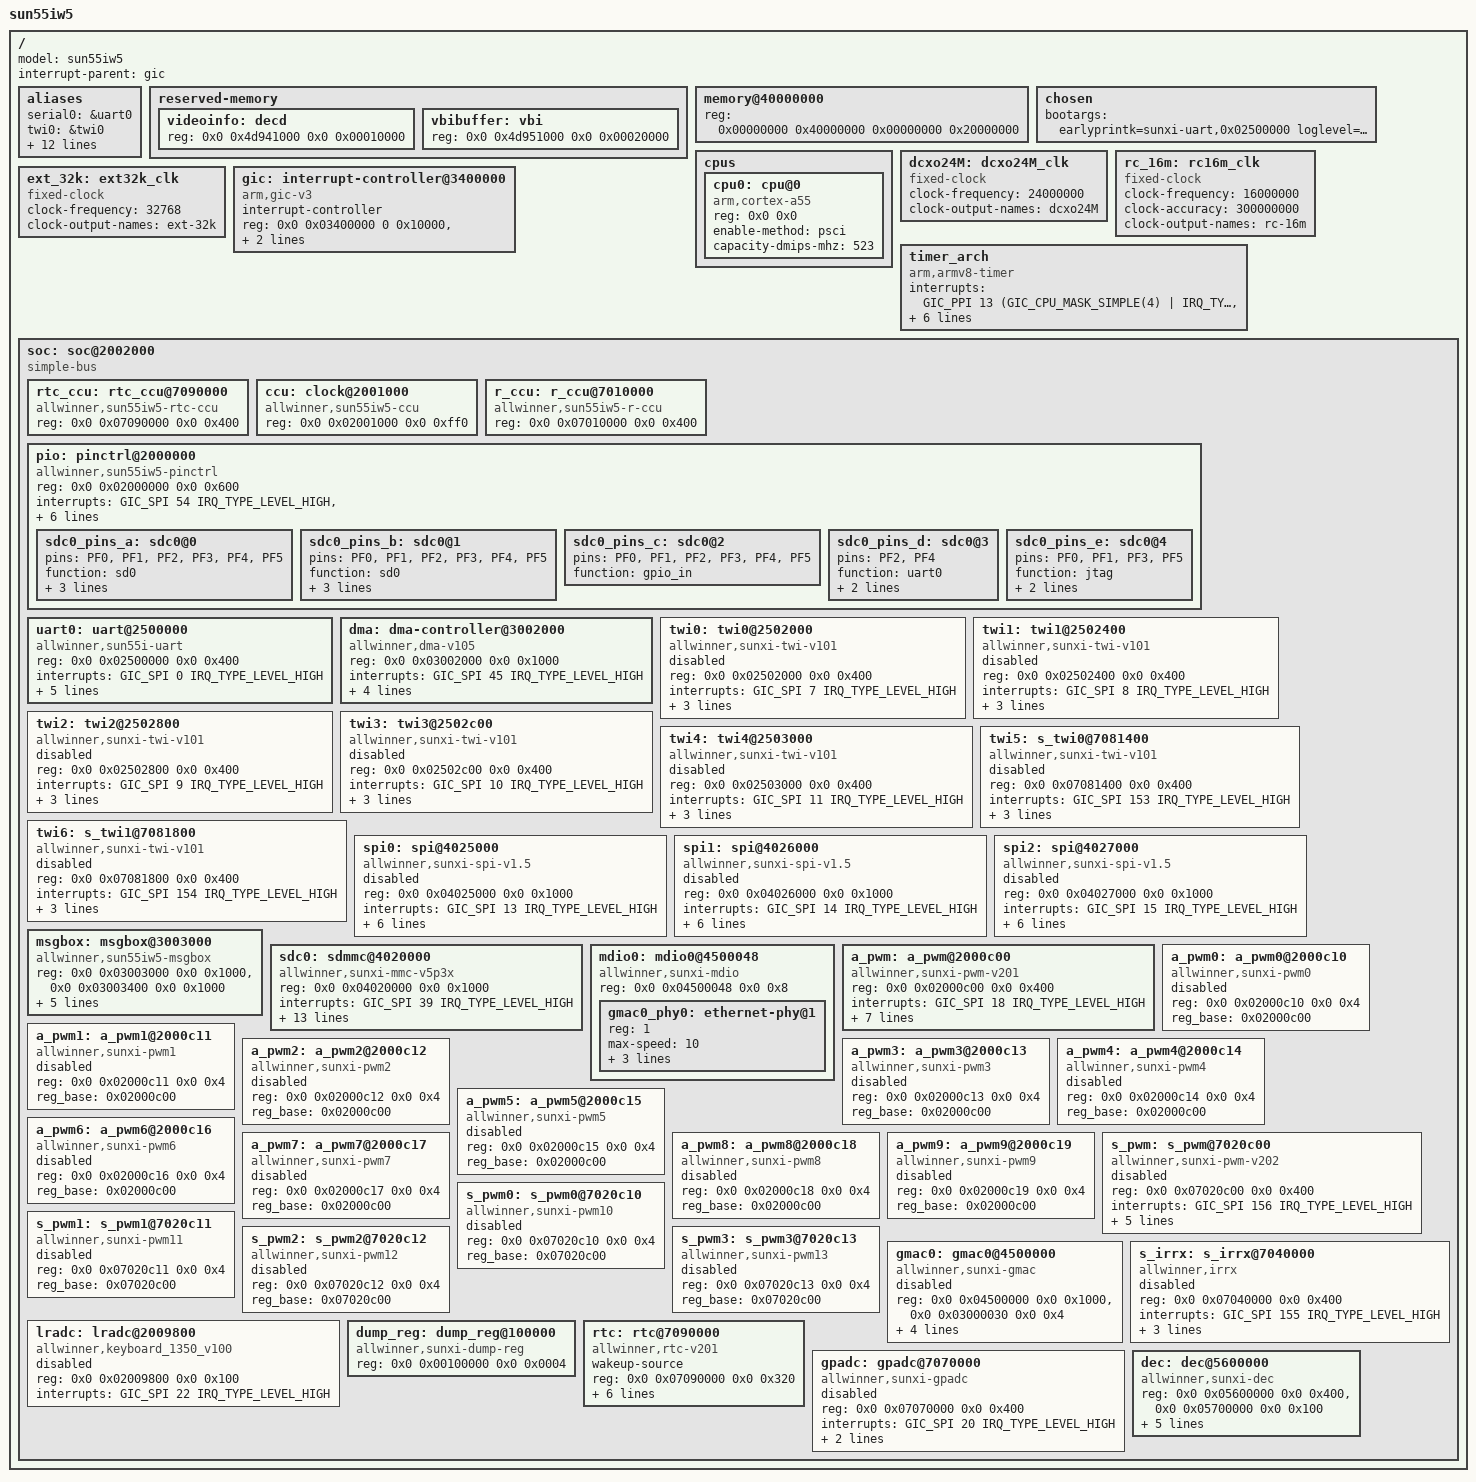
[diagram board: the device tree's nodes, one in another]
// SPDX-License-Identifier: (GPL-2.0+ or MIT)
/*
 * Copyright (C) 2023 zhaozeyan@allwinnertech.com
 */

#include <dt-bindings/clock/sun55iw5-ccu.h>
#include <dt-bindings/clock/sun55iw5-rtc.h>
#include <dt-bindings/clock/sun55iw5-r-ccu.h>
#include <dt-bindings/reset/sun55iw5-ccu.h>
#include <dt-bindings/reset/sun55iw5-r-ccu.h>
#include <dt-bindings/gpio/gpio.h>
#include <dt-bindings/gpio/sun4i-gpio.h>
#include <dt-bindings/interrupt-controller/arm-gic.h>
#include <dt-bindings/thermal/thermal.h>
#include <dt-bindings/spi/sunxi-spi.h>

/ {
	model = "sun55iw5";
	interrupt-parent = <&gic>;
	#address-cells = <2>;
	#size-cells = <2>;

	aliases {
		serial0 = &uart0;
		twi0 = &twi0;
		twi1 = &twi1;
		twi2 = &twi2;
		twi3 = &twi3;
		twi4 = &twi4;
		twi5 = &twi5;
		twi6 = &twi6;
		spi0 = &spi0;
		spi1 = &spi1;
		spi2 = &spi2;
		ir1 = &s_irrx;
		gpadc0 = &gpadc;
		dec = &dec;
	};

	reserved-memory {
		#address-cells = <2>;
		#size-cells = <2>;
		ranges;
		videoinfo: decd {
			reg = <0x0 0x4d941000 0x0 0x00010000>;
		};
		vbibuffer: vbi {
			reg = <0x0 0x4d951000 0x0 0x00020000>;
		};
	};

	memory@40000000 {
		device_type = "memory";
		reg = <0x00000000 0x40000000 0x00000000 0x20000000>;
	};

	chosen {
		bootargs = "earlyprintk=sunxi-uart,0x02500000 loglevel=8 initcall_debug=1 console=ttyS0 init=/init";
	};

	cpus {
		#address-cells = <2>;
		#size-cells = <0>;

		cpu0: cpu@0 {
			device_type = "cpu";
			compatible = "arm,cortex-a55";
			reg = <0x0 0x0>;
			enable-method = "psci";
			capacity-dmips-mhz = <523>;
		};
	};

	dcxo24M: dcxo24M_clk {
		#clock-cells = <0>;
		compatible = "fixed-clock";
		clock-frequency = <24000000>;
		clock-output-names = "dcxo24M";
	};

	rc_16m: rc16m_clk {
		#clock-cells = <0>;
		compatible = "fixed-clock";
		clock-frequency = <16000000>;
		clock-accuracy = <300000000>;
		clock-output-names = "rc-16m";
	};

	ext_32k: ext32k_clk {
		#clock-cells = <0>;
		compatible = "fixed-clock";
		clock-frequency = <32768>;
		clock-output-names = "ext-32k";
	};

	gic: interrupt-controller@3400000 {
		compatible = "arm,gic-v3";
		#interrupt-cells = <3>;
		#address-cells = <0>;
		interrupt-controller;
		reg = <0x0 0x03400000 0 0x10000>, /* GIC Dist */
		      <0x0 0x03440000 0 0xFF004>; /* GIC Re */
		interrupt-parent = <&gic>;
	};

	timer_arch {
		compatible = "arm,armv8-timer";
		interrupts = <GIC_PPI 13 (GIC_CPU_MASK_SIMPLE(4) | IRQ_TYPE_LEVEL_LOW)>,
			   <GIC_PPI 14 (GIC_CPU_MASK_SIMPLE(4) | IRQ_TYPE_LEVEL_LOW)>,
			   <GIC_PPI 11 (GIC_CPU_MASK_SIMPLE(4) | IRQ_TYPE_LEVEL_LOW)>,
			   <GIC_PPI 10 (GIC_CPU_MASK_SIMPLE(4) | IRQ_TYPE_LEVEL_LOW)>;
		clock-frequency = <24000000>;
		interrupt-parent = <&gic>;
		arm,no-tick-in-suspend;
	};

	soc: soc@2002000 {
		compatible = "simple-bus";
		#address-cells = <2>;
		#size-cells = <2>;
		ranges;
		device_type = "soc";

		rtc_ccu: rtc_ccu@7090000 {
			compatible = "allwinner,sun55iw5-rtc-ccu";
			reg = <0x0 0x07090000 0x0 0x400>;
			#clock-cells = <1>;
			#reset-cells = <1>;
		};

		ccu: clock@2001000 {
			compatible = "allwinner,sun55iw5-ccu";
			reg = <0x0 0x02001000 0x0 0xff0>;
			#clock-cells = <1>;
			#reset-cells = <1>;
		};

		r_ccu: r_ccu@7010000 {
			compatible = "allwinner,sun55iw5-r-ccu";
			reg = <0x0 0x07010000 0x0 0x400>;
			#clock-cells = <1>;
			#reset-cells = <1>;
		};

		pio: pinctrl@2000000 {
			compatible = "allwinner,sun55iw5-pinctrl";
			reg = <0x0 0x02000000 0x0 0x600>;
			interrupts = <GIC_SPI 54 IRQ_TYPE_LEVEL_HIGH>,
				   <GIC_SPI 58 IRQ_TYPE_LEVEL_HIGH>,
				   <GIC_SPI 60 IRQ_TYPE_LEVEL_HIGH>;
			clocks = <&ccu CLK_APB1>, <&dcxo24M>, <&ext_32k>;
			clock-names = "apb", "hosc", "losc";
			device_type = "pio";
			gpio-controller;
			interrupt-controller;
			#interrupt-cells = <3>;
			#address-cells = <0>;
			#gpio-cells = <3>;
			input-debounce = <0 0 0 0 1000 0 0 0 0>;

			sdc0_pins_a: sdc0@0 {
				pins = "PF0", "PF1", "PF2",
						"PF3", "PF4", "PF5";
				function = "sd0";
				drive-strength = <40>;
				bias-pull-up;
				power-source = <3300>;
			};

			sdc0_pins_b: sdc0@1 {
				pins = "PF0", "PF1", "PF2",
						"PF3", "PF4", "PF5";
				function = "sd0";
				drive-strength = <40>;
				bias-pull-up;
				power-source = <1800>;
			};

			sdc0_pins_c: sdc0@2 {
				pins = "PF0", "PF1", "PF2",
						"PF3", "PF4", "PF5";
				function = "gpio_in";
			};

			/* TODO: add jtag pin */
			sdc0_pins_d: sdc0@3 {
				pins = "PF2", "PF4";
				function = "uart0";
				drive-strength = <10>;
				bias-pull-up;
			};

			sdc0_pins_e: sdc0@4 {
				pins = "PF0", "PF1", "PF3",
						"PF5";
				function = "jtag";
				drive-strength = <10>;
				bias-pull-up;
			};

		};

		uart0: uart@2500000 {
			compatible = "allwinner,sun55i-uart";
			device_type = "uart0";
			reg = <0x0 0x02500000 0x0 0x400>;
			interrupts = <GIC_SPI 0 IRQ_TYPE_LEVEL_HIGH>;
			sunxi,uart-fifosize = <64>;
			clocks = <&ccu CLK_BUS_UART0>;
			clock-names = "uart0";
			resets = <&ccu RST_BUS_UART0>;
			uart0_port = <0>;
			uart0_type = <2>;
			status = "okay";
		};

		dma:dma-controller@3002000 {
			compatible = "allwinner,dma-v105";
			reg = <0x0 0x03002000 0x0 0x1000>;
			interrupts = <GIC_SPI 45 IRQ_TYPE_LEVEL_HIGH>;
			clocks = <&ccu CLK_DMA>, <&ccu CLK_MBUS_DMA>;
			clock-names = "bus", "mbus";
			dma-channels = <8>;
			dma-requests = <54>;
			resets = <&ccu RST_BUS_DMA>;
			#dma-cells = <1>;
			status = "okay";
		};

		twi0: twi0@2502000 {
			#address-cells = <1>;
			#size-cells = <0>;
			compatible = "allwinner,sunxi-twi-v101";
			device_type = "twi0";
			reg = <0x0 0x02502000 0x0 0x400>;
			interrupts = <GIC_SPI 7 IRQ_TYPE_LEVEL_HIGH>;
			clocks = <&ccu CLK_TWI0>;
			clock-names = "bus";
			resets = <&ccu RST_BUS_TWI0>;
			dmas = <&dma 43>, <&dma 43>;
			dma-names = "tx", "rx";
			status = "disabled";
		};

		twi1: twi1@2502400 {
			#address-cells = <1>;
			#size-cells = <0>;
			compatible = "allwinner,sunxi-twi-v101";
			device_type = "twi1";
			reg = <0x0 0x02502400 0x0 0x400>;
			interrupts = <GIC_SPI 8 IRQ_TYPE_LEVEL_HIGH>;
			clocks = <&ccu CLK_TWI1>;
			clock-names = "bus";
			resets = <&ccu RST_BUS_TWI1>;
			dmas = <&dma 44>, <&dma 44>;
			dma-names = "tx", "rx";
			status = "disabled";
		};

		twi2: twi2@2502800 {
			#address-cells = <1>;
			#size-cells = <0>;
			compatible = "allwinner,sunxi-twi-v101";
			device_type = "twi2";
			reg = <0x0 0x02502800 0x0 0x400>;
			interrupts = <GIC_SPI 9 IRQ_TYPE_LEVEL_HIGH>;
			clocks = <&ccu CLK_TWI2>;
			clock-names = "bus";
			resets = <&ccu RST_BUS_TWI2>;
			dmas = <&dma 45>, <&dma 45>;
			dma-names = "tx", "rx";
			status = "disabled";
		};

		twi3: twi3@2502c00 {
			#address-cells = <1>;
			#size-cells = <0>;
			compatible = "allwinner,sunxi-twi-v101";
			device_type = "twi3";
			reg = <0x0 0x02502c00 0x0 0x400>;
			interrupts = <GIC_SPI 10 IRQ_TYPE_LEVEL_HIGH>;
			clocks = <&ccu CLK_TWI3>;
			clock-names = "bus";
			resets = <&ccu RST_BUS_TWI3>;
			dmas = <&dma 46>, <&dma 46>;
			dma-names = "tx", "rx";
			status = "disabled";
		};

		twi4: twi4@2503000 {
			#address-cells = <1>;
			#size-cells = <0>;
			compatible = "allwinner,sunxi-twi-v101";
			device_type = "twi4";
			reg = <0x0 0x02503000 0x0 0x400>;
			interrupts = <GIC_SPI 11 IRQ_TYPE_LEVEL_HIGH>;
			clocks = <&ccu CLK_TWI4>;
			clock-names = "bus";
			resets = <&ccu RST_BUS_TWI4>;
			dmas = <&dma 47>, <&dma 47>;
			dma-names = "tx", "rx";
			status = "disabled";
		};

		twi5: s_twi0@7081400 {
			#address-cells = <1>;
			#size-cells = <0>;
			compatible = "allwinner,sunxi-twi-v101";
			device_type = "twi5";
			reg = <0x0 0x07081400 0x0 0x400>;
			interrupts = <GIC_SPI 153 IRQ_TYPE_LEVEL_HIGH>;
			clocks = <&r_ccu CLK_R_TWI0>;
			clock-names = "bus";
			resets = <&r_ccu RST_BUS_R_TWI0>;
			dmas = <&dma 50>, <&dma 50>;
			dma-names = "tx", "rx";
			status = "disabled";
		};

		twi6: s_twi1@7081800 {
			#address-cells = <1>;
			#size-cells = <0>;
			compatible = "allwinner,sunxi-twi-v101";
			device_type = "twi6";
			reg = <0x0 0x07081800 0x0 0x400>;
			interrupts = <GIC_SPI 154 IRQ_TYPE_LEVEL_HIGH>;
			clocks = <&r_ccu CLK_R_TWI1>;
			clock-names = "bus";
			resets = <&r_ccu RST_BUS_R_TWI1>;
			dmas = <&dma 51>, <&dma 51>;
			dma-names = "tx", "rx";
			status = "disabled";
		};

		spi0: spi@4025000 {
			#address-cells = <1>;
			#size-cells = <0>;
			compatible = "allwinner,sunxi-spi-v1.5";
			reg = <0x0 0x04025000 0x0 0x1000>;
			interrupts = <GIC_SPI 13 IRQ_TYPE_LEVEL_HIGH>;
			clocks = <&ccu CLK_PLL_PERI0_300M>, <&ccu CLK_SPI0>, <&ccu CLK_BUS_SPI0>, <&ccu CLK_AHB>;
			clock-names = "pll", "mod", "bus", "ahb";
			resets = <&ccu RST_BUS_SPI0>;
			dmas = <&dma 22>, <&dma 22>;
			dma-names = "tx", "rx";
			clock-frequency = <100000000>;
			sunxi,spi-num-cs = <2>;
			status = "disabled";
		};

		spi1: spi@4026000 {
			#address-cells = <1>;
			#size-cells = <0>;
			compatible = "allwinner,sunxi-spi-v1.5";
			reg = <0x0 0x04026000 0x0 0x1000>;
			interrupts = <GIC_SPI 14 IRQ_TYPE_LEVEL_HIGH>;
			clocks = <&ccu CLK_PLL_PERI0_300M>, <&ccu CLK_SPI1>, <&ccu CLK_BUS_SPI1>, <&ccu CLK_AHB>;
			clock-names = "pll", "mod", "bus", "ahb";
			resets = <&ccu RST_BUS_SPI1>;
			dmas = <&dma 23>, <&dma 23>;
			dma-names = "tx", "rx";
			clock-frequency = <100000000>;
			sunxi,spi-num-cs = <1>;
			status = "disabled";
		};

		spi2: spi@4027000 {
			#address-cells = <1>;
			#size-cells = <0>;
			compatible = "allwinner,sunxi-spi-v1.5";
			reg = <0x0 0x04027000 0x0 0x1000>;
			interrupts = <GIC_SPI 15 IRQ_TYPE_LEVEL_HIGH>;
			clocks = <&ccu CLK_PLL_PERI0_300M>, <&ccu CLK_SPI2>, <&ccu CLK_BUS_SPI2>, <&ccu CLK_AHB>;
			clock-names = "pll", "mod", "bus", "ahb";
			resets = <&ccu RST_BUS_SPI2>;
			dmas = <&dma 24>, <&dma 24>;
			dma-names = "tx", "rx";
			clock-frequency = <100000000>;
			sunxi,spi-num-cs = <1>;
			status = "disabled";
		};

		/*
		 * channel0~3  : arm -> cpus
		 */
		msgbox: msgbox@3003000 {
			compatible = "allwinner,sun55iw5-msgbox";
			#mbox-cells = <1>;
			reg = <0x0 0x03003000 0x0 0x1000>,
			      <0x0 0x03003400 0x0 0x1000>;
			interrupts = <GIC_SPI 46 IRQ_TYPE_LEVEL_HIGH>,
					<GIC_SPI 108 IRQ_TYPE_LEVEL_HIGH>;
			clocks = <&ccu CLK_MSGBOX>;
			clock-names = "msgbox";
			resets = <&ccu RST_BUS_MSGBOX>;
			reset-names = "rst";
			local_id = <0>;
			status = "okay";
		};

		sdc0: sdmmc@4020000 {
			compatible = "allwinner,sunxi-mmc-v5p3x";
			device_type = "sdc0";
			reg = <0x0 0x04020000 0x0 0x1000>;
			interrupts = <GIC_SPI 39 IRQ_TYPE_LEVEL_HIGH>;
			clocks = <&dcxo24M>,
				 <&ccu CLK_SMHC0>,
				 <&ccu CLK_BUS_SMHC0>;
			clock-names = "osc24m","mmc","ahb";
			resets = <&ccu RST_BUS_SMHC0>;
			reset-names = "rst";
			pinctrl-names = "default","mmc_1v8","sleep","uart_jtag";
			pinctrl-0 = <&sdc0_pins_a>;
			pinctrl-1 = <&sdc0_pins_b>;
			pinctrl-2 = <&sdc0_pins_c>;
			pinctrl-3 = <&sdc0_pins_d &sdc0_pins_e>;
			max-frequency = <50000000>;
			bus-width = <4>;
			req-page-count = <2>;
			/*non-removable;*/
			/*broken-cd;*/
			/*cd-inverted*/
			/*cd-gpios = <&pio PF 6 GPIO_ACTIVE_LOW>;*/
			/* vmmc-supply = <&reg_3p3v>;*/
			/* vqmc-supply = <&reg_3p3v>;*/
			/* vdmc-supply = <&reg_3p3v>;*/
			/*vmmc = "vcc-card";*/
			/*vqmc = "";*/
			/*vdmc = "";*/
			cap-sd-highspeed;
			cap-wait-while-busy;
			/*sd-uhs-sdr50;*/
			/*sd-uhs-ddr50;*/
			/*cap-sdio-irq;*/
			/*keep-power-in-suspend;*/
			/*ignore-pm-notify;*/
			/*sunxi-power-save-mode;*/
			/*sunxi-dly-400k = <1 0 0 0>; */
			/*sunxi-dly-26M  = <1 0 0 0>;*/
			/*sunxi-dly-52M  = <1 0 0 0>;*/
			/*sunxi-dly-52M-ddr4  = <1 0 0 0>;*/
			/*sunxi-dly-52M-ddr8  = <1 0 0 0>;*/
			/*sunxi-dly-104M  = <1 0 0 0>;*/
			/*sunxi-dly-208M  = <1 0 0 0>;*/
			/*sunxi-dly-104M-ddr  = <1 0 0 0>;*/
			/*sunxi-dly-208M-ddr  = <1 0 0 0>;*/
			ctl-spec-caps = <0x408>;
			status = "okay";
		};

		mdio0: mdio0@4500048 {
			compatible = "allwinner,sunxi-mdio";
			#address-cells = <1>;
			#size-cells = <0>;
			reg = <0x0 0x04500048 0x0 0x8>;
			status = "okay";
			gmac0_phy0: ethernet-phy@1 {
				/* RTL8211F (0x001cc916) */
				reg = <1>;
				max-speed = <10>;  /* Max speed capability in FPGA */
				reset-gpios = <&pio PA 14 GPIO_ACTIVE_LOW>;
				/* PHY datasheet rst time */
				reset-assert-us = <10000>;
				reset-deassert-us = <150000>;
			};
		};

		a_pwm: a_pwm@2000c00 {
			#pwm-cells = <0x3>;
			compatible = "allwinner,sunxi-pwm-v201";
			reg = <0x0 0x02000c00 0x0 0x400>;
			interrupts = <GIC_SPI 18 IRQ_TYPE_LEVEL_HIGH>;
			clocks = <&ccu CLK_PWM>;
			resets = <&ccu RST_BUS_PWM>;
			pwm-number = <10>;
			pwm-base = <0x0>;
			sunxi-pwms = <&a_pwm0>, <&a_pwm1>, <&a_pwm2>, <&a_pwm3>,
			<&a_pwm4>, <&a_pwm5>, <&a_pwm6>, <&a_pwm7>, <&a_pwm8>, <&a_pwm9>;
			status = "okay";
		};

		a_pwm0: a_pwm0@2000c10 {
			compatible = "allwinner,sunxi-pwm0";
			pinctrl-names = "active", "sleep";
			reg = <0x0 0x02000c10 0x0 0x4>;
			reg_base = <0x02000c00>;
			status = "disabled";
		};

		a_pwm1: a_pwm1@2000c11 {
			compatible = "allwinner,sunxi-pwm1";
			pinctrl-names = "active", "sleep";
			reg = <0x0 0x02000c11 0x0 0x4>;
			reg_base = <0x02000c00>;
			status = "disabled";
		};

		a_pwm2: a_pwm2@2000c12 {
			compatible = "allwinner,sunxi-pwm2";
			pinctrl-names = "active", "sleep";
			reg = <0x0 0x02000c12 0x0 0x4>;
			reg_base = <0x02000c00>;
			status = "disabled";
		};

		a_pwm3: a_pwm3@2000c13 {
			compatible = "allwinner,sunxi-pwm3";
			pinctrl-names = "active", "sleep";
			reg = <0x0 0x02000c13 0x0 0x4>;
			reg_base = <0x02000c00>;
			status = "disabled";
		};

		a_pwm4: a_pwm4@2000c14 {
			compatible = "allwinner,sunxi-pwm4";
			pinctrl-names = "active", "sleep";
			reg = <0x0 0x02000c14 0x0 0x4>;
			reg_base = <0x02000c00>;
			status = "disabled";
		};

		a_pwm5: a_pwm5@2000c15 {
			compatible = "allwinner,sunxi-pwm5";
			pinctrl-names = "active", "sleep";
			reg = <0x0 0x02000c15 0x0 0x4>;
			reg_base = <0x02000c00>;
			status = "disabled";
		};

		a_pwm6: a_pwm6@2000c16 {
			compatible = "allwinner,sunxi-pwm6";
			pinctrl-names = "active", "sleep";
			reg = <0x0 0x02000c16 0x0 0x4>;
			reg_base = <0x02000c00>;
			status = "disabled";
		};

		a_pwm7: a_pwm7@2000c17 {
			compatible = "allwinner,sunxi-pwm7";
			pinctrl-names = "active", "sleep";
			reg = <0x0 0x02000c17 0x0 0x4>;
			reg_base = <0x02000c00>;
			status = "disabled";
		};

		a_pwm8: a_pwm8@2000c18 {
			compatible = "allwinner,sunxi-pwm8";
			pinctrl-names = "active", "sleep";
			reg = <0x0 0x02000c18 0x0 0x4>;
			reg_base = <0x02000c00>;
			status = "disabled";
		};

		a_pwm9: a_pwm9@2000c19 {
			compatible = "allwinner,sunxi-pwm9";
			pinctrl-names = "active", "sleep";
			reg = <0x0 0x02000c19 0x0 0x4>;
			reg_base = <0x02000c00>;
			status = "disabled";
		};

		s_pwm: s_pwm@7020c00 {
			#pwm-cells = <0x3>;
			compatible = "allwinner,sunxi-pwm-v202";
			reg = <0x0 0x07020c00 0x0 0x400>;
			interrupts = <GIC_SPI 156 IRQ_TYPE_LEVEL_HIGH>;
			clocks = <&r_ccu CLK_R_PWM>,<&r_ccu CLK_BUS_R_PWM>;
			clock-names = "clk_pwm","clk_bus_pwm";
			resets = <&r_ccu RST_BUS_R_PWM>;
			pwm-number = <2>;
			pwm-base = <0xb>;
			sunxi-pwms = <&s_pwm0>, <&s_pwm1>, <&s_pwm2>, <&s_pwm3>;
			status = "disabled";
		};

		s_pwm0: s_pwm0@7020c10 {
			compatible = "allwinner,sunxi-pwm10";
			pinctrl-names = "active", "sleep";
			reg = <0x0 0x07020c10 0x0 0x4>;
			reg_base = <0x07020c00>;
			status = "disabled";
		};

		s_pwm1: s_pwm1@7020c11 {
			compatible = "allwinner,sunxi-pwm11";
			pinctrl-names = "active", "sleep";
			reg = <0x0 0x07020c11 0x0 0x4>;
			reg_base = <0x07020c00>;
			status = "disabled";
		};

		s_pwm2: s_pwm2@7020c12 {
			compatible = "allwinner,sunxi-pwm12";
			pinctrl-names = "active", "sleep";
			reg = <0x0 0x07020c12 0x0 0x4>;
			reg_base = <0x07020c00>;
			status = "disabled";
		};

		s_pwm3: s_pwm3@7020c13 {
			compatible = "allwinner,sunxi-pwm13";
			pinctrl-names = "active", "sleep";
			reg = <0x0 0x07020c13 0x0 0x4>;
			reg_base = <0x07020c00>;
			status = "disabled";
		};

		gmac0: gmac0@4500000 {
			compatible = "allwinner,sunxi-gmac";
			reg = <0x0 0x04500000 0x0 0x1000>,
			      <0x0 0x03000030 0x0 0x4>;
			interrupts = <GIC_SPI 16 IRQ_TYPE_LEVEL_HIGH>;
			interrupt-names = "gmacirq";
			clocks = <&ccu CLK_GMAC0>, <&ccu CLK_GMAC0_25M>;
			clock-names = "gmac", "phy25m";
			resets = <&ccu RST_BUS_GMAC0>;
			phy-handle = <&gmac0_phy0>;
			status = "disabled";
		};

		s_irrx: s_irrx@7040000 {
			compatible = "allwinner,irrx";
			reg = <0x0 0x07040000 0x0 0x400>;
			interrupts = <GIC_SPI 155 IRQ_TYPE_LEVEL_HIGH>;
			clocks = <&r_ccu CLK_BUS_R_IRRX>, <&dcxo24M>, <&r_ccu CLK_R_IRRX>;
			clock-names = "bus", "pclk", "mclk";
			resets = <&r_ccu RST_BUS_R_IRRX>;
			status = "disabled";
		};

		lradc: lradc@2009800 {
			compatible = "allwinner,keyboard_1350_v100";
			reg = <0x0 0x02009800 0x0 0x100>;
			interrupts = <GIC_SPI 22 IRQ_TYPE_LEVEL_HIGH>;
			status = "disabled";
		};

		dump_reg:dump_reg@100000 {
			 compatible = "allwinner,sunxi-dump-reg";
			 reg = <0x0 0x00100000 0x0 0x0004>;
		};

		rtc: rtc@7090000 {
			compatible = "allwinner,rtc-v201";
			device_type = "rtc";
			wakeup-source;
			reg = <0x0 0x07090000 0x0 0x320>;
			interrupts = <GIC_SPI 147 IRQ_TYPE_LEVEL_HIGH>;
			clocks = <&r_ccu CLK_R_RTC>, <&rtc_ccu CLK_RTC_1K>, <&rtc_ccu CLK_RTC_SPI>;
			clock-names = "r-ahb-rtc", "rtc-1k", "rtc-spi";
			resets = <&r_ccu RST_BUS_R_RTC>;
			gpr_cur_pos = <6>;
			gpr_bootcount_pos = <7>;
		};

		gpadc: gpadc@7070000 {
			compatible = "allwinner,sunxi-gpadc";
			reg = <0x0 0x07070000 0x0 0x400>;
			interrupts = <GIC_SPI 20 IRQ_TYPE_LEVEL_HIGH>;
			clocks = <&ccu CLK_R_GPADC>;
			clock-names = "bus";
			resets = <&ccu RST_BUS_R_GPADC>;
			status = "disabled";
		};
		dec: dec@5600000 {
			#address-cells = <2>;
			#size-cells = <2>;
			ranges;

			compatible = "allwinner,sunxi-dec", "simple-bus";
			reg = <0x0 0x05600000 0x0 0x400>, /*tv disp top*/
				<0x0 0x05700000 0x0 0x100>;/*afbd*/
			interrupts = <GIC_SPI 110 IRQ_TYPE_LEVEL_HIGH>;
			clocks = <&ccu CLK_AFBD>,<&ccu CLK_DISP>;
			clock-names = "clk_afbd", "clk_bus_disp";
			resets = <&ccu RST_BUS_DISP>;
			reset-names = "rst_bus_disp";
			clock-frequency = <200000000>;

			/*iommus = <&mmu_aw 2 0>;*/
			memory-region = <&videoinfo &vbibuffer>;

		};
	};
};
